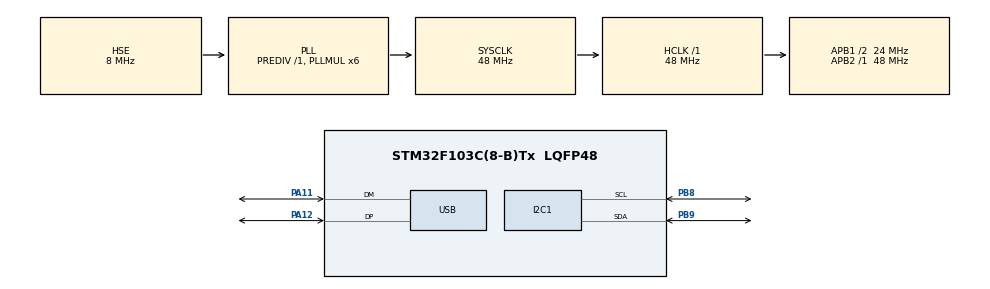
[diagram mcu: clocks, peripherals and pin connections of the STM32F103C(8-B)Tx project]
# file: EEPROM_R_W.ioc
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I2C1.I2C_Mode=I2C_Fast
Mcu.Family=STM32F1
Mcu.Name=STM32F103C(8-B)Tx
Mcu.Package=LQFP48
NVIC.PriorityGroup=NVIC_PRIORITYGROUP_4
NVIC.USB_LP_CAN1_RX0_IRQn=true\:0\:0\:false\:false\:true\:false\:true\:true
PA11.Mode=Device
PA11.Signal=USB_DM
PA12.Mode=Device
PA12.Signal=USB_DP
PB8.Mode=I2C
PB8.Signal=I2C1_SCL
PB9.Mode=I2C
PB9.Signal=I2C1_SDA
PC14-OSC32_IN.Mode=LSE-External-Oscillator
PC14-OSC32_IN.Signal=RCC_OSC32_IN
PC15-OSC32_OUT.Mode=LSE-External-Oscillator
PC15-OSC32_OUT.Signal=RCC_OSC32_OUT
PD0-OSC_IN.Mode=HSE-External-Oscillator
PD0-OSC_IN.Signal=RCC_OSC_IN
PD1-OSC_OUT.Mode=HSE-External-Oscillator
PD1-OSC_OUT.Signal=RCC_OSC_OUT
ProjectManager.HeapSize=0x200
ProjectManager.StackSize=0x400
ProjectManager.TargetToolchain=STM32CubeIDE
RCC.AHBFreq_Value=48000000
RCC.APB1CLKDivider=RCC_HCLK_DIV2
RCC.APB1Freq_Value=24000000
RCC.APB1TimFreq_Value=48000000
RCC.APB2Freq_Value=48000000
RCC.APB2TimFreq_Value=48000000
RCC.HCLKFreq_Value=48000000
RCC.PLLMUL=RCC_PLL_MUL6
RCC.PLLSourceVirtual=RCC_PLLSOURCE_HSE
RCC.SYSCLKFreq_VALUE=48000000
RCC.SYSCLKSource=RCC_SYSCLKSOURCE_PLLCLK
RCC.USBFreq_Value=48000000
USB_DEVICE.CLASS_NAME_FS=CDC
USB_DEVICE.VirtualMode=Cdc
USB_DEVICE.VirtualModeFS=Cdc_FS
VP_RTC_No_RTC_Output.Mode=RTC_OUT_NO
VP_RTC_VS_RTC_Activate.Mode=RTC_Enabled
VP_SYS_VS_ND.Mode=No_Debug
VP_USB_DEVICE_VS_USB_DEVICE_CDC_FS.Mode=CDC_FS
board=custom

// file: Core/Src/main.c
/* USER CODE BEGIN Header */
/**
 ******************************************************************************
 * @file           : main.c
 * @brief          : Main program body
 ******************************************************************************
 * @attention
 *
 * Copyright (c) 2023 STMicroelectronics.
 * All rights reserved.
 *
 * This software is licensed under terms that can be found in the LICENSE file
 * in the root directory of this software component.
 * If no LICENSE file comes with this software, it is provided AS-IS.
 *
 ******************************************************************************
 */
/* USER CODE END Header */
#include "main.h"
#include "usb_device.h"

/* USER CODE BEGIN Includes */
#include "usbd_cdc_if.h"
#include "stdlib.h"
#include <stdio.h>
/* USER CODE END Includes */

I2C_HandleTypeDef hi2c1;

RTC_HandleTypeDef hrtc;

void SystemClock_Config(void);
static void MX_GPIO_Init(void);
static void MX_RTC_Init(void);
static void MX_I2C1_Init(void);

/* USER CODE BEGIN 0 */

uint8_t start = 0;
/* USER CODE END 0 */

int main(void)
{

  /* MCU Configuration--------------------------------------------------------*/

  /* Reset of all peripherals, Initializes the Flash interface and the Systick. */
  HAL_Init();

  /* Configure the system clock */
  SystemClock_Config();

  /* Initialize all configured peripherals */
  MX_GPIO_Init();
  MX_I2C1_Init();
  MX_RTC_Init();
  MX_USB_DEVICE_Init();

  /* Infinite loop */
  /* USER CODE BEGIN WHILE */

  while (1)
  {
	  HandleCommand();

    /* USER CODE END WHILE */

  }
}

void SystemClock_Config(void)
{
  RCC_OscInitTypeDef RCC_OscInitStruct = {0};
  RCC_ClkInitTypeDef RCC_ClkInitStruct = {0};
  RCC_PeriphCLKInitTypeDef PeriphClkInit = {0};

  /** Initializes the RCC Oscillators according to the specified parameters
   * in the RCC_OscInitTypeDef structure.
   */
  RCC_OscInitStruct.OscillatorType = RCC_OSCILLATORTYPE_LSI | RCC_OSCILLATORTYPE_HSE;
  RCC_OscInitStruct.HSEState = RCC_HSE_ON;
  RCC_OscInitStruct.HSEPredivValue = RCC_HSE_PREDIV_DIV1;
  RCC_OscInitStruct.HSIState = RCC_HSI_ON;
  RCC_OscInitStruct.LSIState = RCC_LSI_ON;
  RCC_OscInitStruct.PLL.PLLState = RCC_PLL_ON;
  RCC_OscInitStruct.PLL.PLLSource = RCC_PLLSOURCE_HSE;
  RCC_OscInitStruct.PLL.PLLMUL = RCC_PLL_MUL6;
  if (HAL_RCC_OscConfig(&RCC_OscInitStruct) != HAL_OK)
  {
    Error_Handler();
  }

  /** Initializes the CPU, AHB and APB buses clocks
   */
  RCC_ClkInitStruct.ClockType = RCC_CLOCKTYPE_HCLK | RCC_CLOCKTYPE_SYSCLK | RCC_CLOCKTYPE_PCLK1 | RCC_CLOCKTYPE_PCLK2;
  RCC_ClkInitStruct.SYSCLKSource = RCC_SYSCLKSOURCE_PLLCLK;
  RCC_ClkInitStruct.AHBCLKDivider = RCC_SYSCLK_DIV1;
  RCC_ClkInitStruct.APB1CLKDivider = RCC_HCLK_DIV2;
  RCC_ClkInitStruct.APB2CLKDivider = RCC_HCLK_DIV1;

  if (HAL_RCC_ClockConfig(&RCC_ClkInitStruct, FLASH_LATENCY_1) != HAL_OK)
  {
    Error_Handler();
  }
  PeriphClkInit.PeriphClockSelection = RCC_PERIPHCLK_RTC | RCC_PERIPHCLK_USB;
  PeriphClkInit.RTCClockSelection = RCC_RTCCLKSOURCE_LSI;
  PeriphClkInit.UsbClockSelection = RCC_USBCLKSOURCE_PLL;
  if (HAL_RCCEx_PeriphCLKConfig(&PeriphClkInit) != HAL_OK)
  {
    Error_Handler();
  }
}

static void MX_I2C1_Init()
{

  hi2c1.Instance = I2C1;
  hi2c1.Init.ClockSpeed = 400000;
  hi2c1.Init.DutyCycle = I2C_DUTYCYCLE_2;
  hi2c1.Init.OwnAddress1 = 0;
  hi2c1.Init.AddressingMode = I2C_ADDRESSINGMODE_7BIT;
  hi2c1.Init.DualAddressMode = I2C_DUALADDRESS_DISABLE;
  hi2c1.Init.OwnAddress2 = 0;
  hi2c1.Init.GeneralCallMode = I2C_GENERALCALL_DISABLE;
  hi2c1.Init.NoStretchMode = I2C_NOSTRETCH_DISABLE;
  if (HAL_I2C_Init(&hi2c1) != HAL_OK)
  {
    Error_Handler();
  }
}

static void MX_RTC_Init(void)
{

  RTC_TimeTypeDef sTime = {0};
  RTC_DateTypeDef DateToUpdate = {0};

  /** Initialize RTC Only
   */
  hrtc.Instance = RTC;
  hrtc.Init.AsynchPrediv = RTC_AUTO_1_SECOND;
  hrtc.Init.OutPut = RTC_OUTPUTSOURCE_NONE;
  if (HAL_RTC_Init(&hrtc) != HAL_OK)
  {
    Error_Handler();
  }

  /** Initialize RTC and set the Time and Date
   */
  sTime.Hours = 0x0;
  sTime.Minutes = 0x0;
  sTime.Seconds = 0x0;

  if (HAL_RTC_SetTime(&hrtc, &sTime, RTC_FORMAT_BCD) != HAL_OK)
  {
    Error_Handler();
  }
  DateToUpdate.WeekDay = RTC_WEEKDAY_MONDAY;
  DateToUpdate.Month = RTC_MONTH_JANUARY;
  DateToUpdate.Date = 0x1;
  DateToUpdate.Year = 0x0;

  if (HAL_RTC_SetDate(&hrtc, &DateToUpdate, RTC_FORMAT_BCD) != HAL_OK)
  {
    Error_Handler();
  }
}

static void MX_GPIO_Init(void)
{

  /* GPIO Ports Clock Enable */
  __HAL_RCC_GPIOC_CLK_ENABLE();
  __HAL_RCC_GPIOD_CLK_ENABLE();
  __HAL_RCC_GPIOA_CLK_ENABLE();
  __HAL_RCC_GPIOB_CLK_ENABLE();
}

/* USER CODE BEGIN 4 */

int _write(int file, char *ptr, int len)
{
  static uint8_t rc = USBD_OK;

  do
  {
    rc = CDC_Transmit_FS(ptr, len);
  } while (USBD_BUSY == rc);

  if (USBD_FAIL == rc)
  {
    /// NOTE: Should never reach here.
    /// TODO: Handle this error.
    return 0;
  }
  return len;
}

/* USER CODE END 4 */

void Error_Handler(void)
{
  __disable_irq();
  while (1)
  {
  }
}
